# A31C11x register map
Vendor: ABOV Semiconductor Co., Ltd.; File version: 1.0
CPU: CM0PLUS r0p1, little endian, no MPU, no FPU, VTOR, 2 interrupt priority bits
Registers are 32-bit, read-write, reset 0x0 unless marked. A register's access mark holds for its fields unless they carry their own. Offsets are from the block's base; [hi:lo] are bit positions; lines under a group give offsets from that group; {n}, {i} and the like mark numbered series; 'fields as' and 'values as' point back to an identical list.

## SCU — System Control Unit
Base 0x40000000
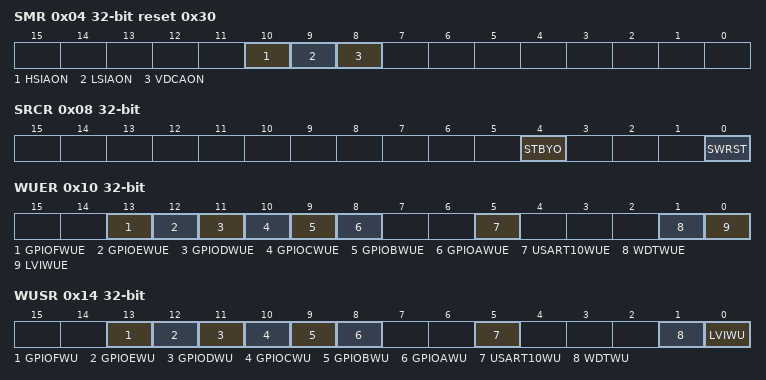
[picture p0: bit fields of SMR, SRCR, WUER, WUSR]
0x04 SMR reset 0x30 — System Mode Register
  [10] HSIAON — HSI enablement in DEEP-SLEEP mode
  [9] LSIAON — LSI enablement in DEEP-SLEEP mode
  [8] VDCAON — VDC enablement in DEEP-SLEEP mode
0x08 SRCR — System reset control Register
  [4] STBYO — Inversion selection for the STBYO pin's output
  [0] SWRST wo — Internal soft reset activation bit (Check SWRST in SCU_RSER for reset)
0x10 WUER — Wake-up Source Enable Register
  [13] GPIOFWUE — Whether or not to use the GPIOF port event as a wake-up source
  [12] GPIOEWUE — Whether or not to use the GPIOE port event as a wake-up source
  [11] GPIODWUE — Whether or not to use the GPIOD port event as a wake-up source
  [10] GPIOCWUE — Whether or not to use the GPIOC port event as a wake-up source
  [9] GPIOBWUE — Whether or not to use the GPIOB port event as a wake-up source
  [8] GPIOAWUE — Whether or not to use the GPIOA port event as a wake-up source
  [5] USART10WUE — Whether or not to use the USART10 event as a wake-up source
  [1] WDTWUE — Whether or not to use the WDT event as a wake-up source
  [0] LVIWUE — Whether or not to use the LVI event as a wake-up source
0x14 WUSR ro — Wake-up Source Status Register
  [13] GPIOFWU — GPIOF port event Wake-up status
  [12] GPIOEWU — GPIOE port event Wake-up status
  [11] GPIODWU — GPIOD port event Wake-up status
  [10] GPIOCWU — GPIOC port event Wake-up status
  [9] GPIOBWU — GPIOB port event Wake-up status
  [8] GPIOAWU — GPIOA port event Wake-up status
  [5] USART10WU — USART10 event Wake-up status
  [1] WDTWU — WDT event Wake-up status
  [0] LVIWU — LVI event Wake-up status
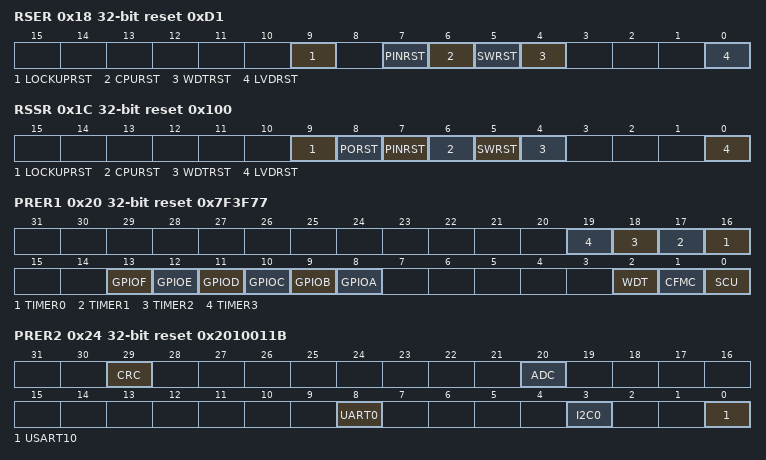
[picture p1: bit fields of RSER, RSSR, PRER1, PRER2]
0x18 RSER reset 0xD1 — Reset Source Enable Register
  [9] LOCKUPRST — Whether to enable or disable the CPU lock-up reset signal
  [7] PINRST — Whether to enable or disable the external-pin reset signal
  [6] CPURST — Whether to enable or disable the CPU request reset signal
  [5] SWRST — Whether to enable or disable the software reset signal
  [4] WDTRST — Whether to enable or disable the WDT reset signal
  [0] LVDRST — Whether to enable or disable the LVD reset signal
0x1C RSSR reset 0x100 — Reset Source Status Register
  [9] LOCKUPRST — Whether or not the CPU lock-up reset has occurred
  [8] PORST — Whether or not the POR reset has occurred
  [7] PINRST — Whether or not the external pin reset has occurred
  [6] CPURST — Whether or not the CPU core reset has occurred
  [5] SWRST — Whether or not the software reset has occurred
  [4] WDTRST — Whether or not the WDT reset has occurred
  [0] LVDRST — Whether or not the LVD reset has occurred
0x20 PRER1 reset 0x7F3F77 — Peripheral Reset Enable Register1
  [n+16] TIMER{n} (n=0..3) — TIMER{n} Reset Mask
  [13] GPIOF — GPIOF Reset Mask
  [12] GPIOE — GPIOE Reset Mask
  [11] GPIOD — GPIOD Reset Mask
  [10] GPIOC — GPIOC Reset Mask
  [9] GPIOB — GPIOB Reset Mask
  [8] GPIOA — GPIOA Reset Mask
  [2] WDT — WDT Reset Mask
  [1] CFMC — CFMC Reset Mask
  [0] SCU — SCU Reset Mask
0x24 PRER2 reset 0x2010011B — Peripheral Reset Setting Register2
  [29] CRC — CRC Reset Mask
  [20] ADC — ADC Reset Mask
  [8] UART0 — UART0 Reset Mask
  [3] I2C0 — I2C0 Reset Mask
  [0] USART10 — USART10 Reset Mask
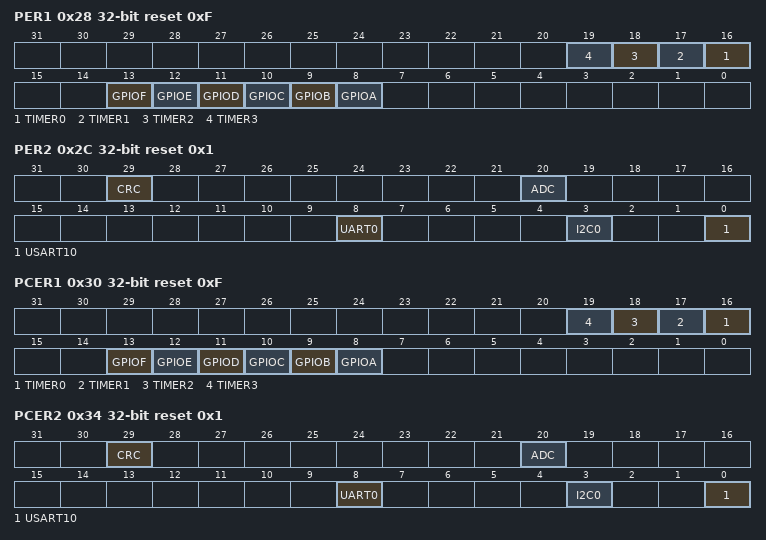
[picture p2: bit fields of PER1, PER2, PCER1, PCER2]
0x28 PER1 reset 0xF — Peripheral Enable Register1
  [n+16] TIMER{n} (n=0..3) — Whether to enable or disable TIMER{n}
  [13] GPIOF — Whether to enable or disable GPIOF
  [12] GPIOE — Whether to enable or disable GPIOE
  [11] GPIOD — Whether to enable or disable GPIOD
  [10] GPIOC — Whether to enable or disable GPIOC
  [9] GPIOB — Whether to enable or disable GPIOB
  [8] GPIOA — Whether to enable or disable GPIOA
0x2C PER2 reset 0x1 — Peripheral Enable Register2
  [29] CRC — Whether to enable or disable CRC
  [20] ADC — Whether to enable or disable ADC
  [8] UART0 — Whether to enable or disable UART0
  [3] I2C0 — Whether to enable or disable I2C0
  [0] USART10 — Whether to enable or disable USART10
0x30 PCER1 reset 0xF — Peripheral Clock Enable Register1
  [n+16] TIMER{n} (n=0..3) — Whether to enable or disable the clock to TIMER{n}
  [13] GPIOF — Whether to enable or disable the clock to GPIOF
  [12] GPIOE — Whether to enable or disable the clock to GPIOE
  [11] GPIOD — Whether to enable or disable the clock to GPIOD
  [10] GPIOC — Whether to enable or disable the clock to GPIOC
  [9] GPIOB — Whether to enable or disable the clock to GPIOB
  [8] GPIOA — Whether to enable or disable the clock to GPIOA
0x34 PCER2 reset 0x1 — Peripheral Clock Enable Register2
  [29] CRC — Whether to enable or disable the clock to CRC
  [20] ADC — Whether to enable or disable the clock to ADC
  [8] UART0 — Whether to enable or disable the clock to UART0
  [3] I2C0 — Whether to enable or disable the clock to I2C0
  [0] USART10 — Whether to enable or disable the clock to USART10
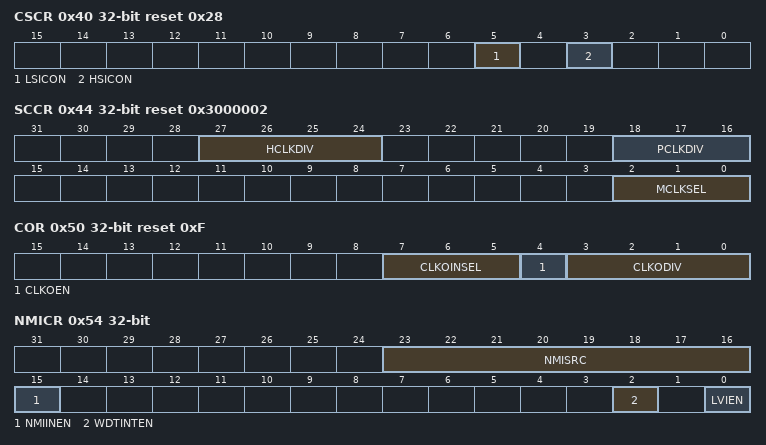
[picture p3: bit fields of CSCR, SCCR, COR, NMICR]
0x40 CSCR reset 0x28 — Clock Source Control Register
  [5] LSICON — Low speed internal oscillator control
  [3] HSICON — High speed internal oscillator control
0x44 SCCR reset 0x3000002 — System clock control register
  [27:24] HCLKDIV — Clock divider for HCLK input
    9=MCLK_DIV_BY_512 (HCLK=MCLK_div_512); 8=MCLK_DIV_BY_256 (HCLK=MCLK_div_256); 7=MCLK_DIV_BY_128 (HCLK=MCLK_div_128); 6=MCLK_DIV_BY_64 (HCLK=MCLK_div_64); 5=MCLK_DIV_BY_32 (HCLK=MCLK_div_32); 4=MCLK_DIV_BY_16 (HCLK=MCLK_div_16); 3=MCLK_DIV_BY_8 (HCLK=MCLK_div_8); 2=MCLK_DIV_BY_4 (HCLK=MCLK_div_4); 1=MCLK_DIV_BY_2 (HCLK=MCLK_div_2); 0=MCLK_DIV_BY_1 (HCLK=MCLK_div_1)
  [18:16] PCLKDIV — Clock divider for PCLK input
    4=HCLK_DIV_BY_16 (PCLK=HCLK_div_16); 3=HCLK_DIV_BY_8 (PCLK=HCLK_div_8); 2=HCLK_DIV_BY_4 (PCLK=HCLK_div_4); 1=HCLK_DIV_BY_2 (PCLK=HCLK_div_2); 0=MCLK_DIV_BY_1 (HCLK=MCLK_div_1)
  [2:0] MCLKSEL — Main system clock selection
    2=HSI (system clock is HSI); 0=LSI (system clock is LSI)
0x50 COR reset 0xF — Clock Output Setting Register
  [7:5] CLKOINSEL — Selection of the clock to send a signal from CLKO
    5=HSI (Output clock is HSI); 4=MCLK (Output clock is MCLK); 0=LSI (Output clock is LSI)
  [4] CLKOEN — Clock output use
  [3:0] CLKODIV — Clock output divider value.
0x54 NMICR — NMI Control Register
  [23:16] NMISRC — NMI source selection bit
  [15] NMIINEN — Whether to enable or disable the NMIs (Interrupts that have been specified as NMI sources)
  [2] WDTINTEN — Whether to enable or disable the WDT interrupt as an NMI
  [0] LVIEN — Whether to enable or disable the LVI error interrupt as an NMI
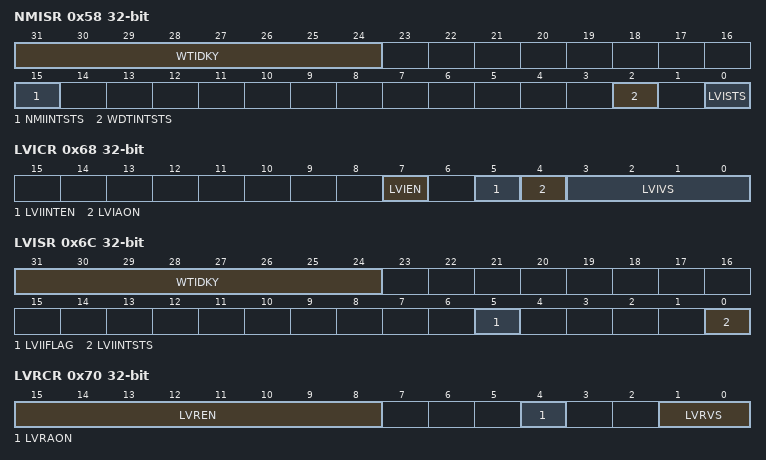
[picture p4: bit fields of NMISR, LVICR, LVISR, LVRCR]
0x58 NMISR — NMI Status Register
  [31:24] WTIDKY wo — Write identification key
  [15] NMIINTSTS ro — Whether or not an NMI has occurred (The flag can be cleared by writing to the triggered NMIs bit.)
  [2] WDTINTSTS — Whether or not the WDT interrupt has occurred
  [0] LVISTS — Whether or not the LVI interrupt has occurred
0x64 VDCCON reset 0x7F — VDC Control Register
  [7:0] VDCWDLY — VDC Warm-up Delay Count Value
0x68 LVICR — Low Voltage Indicator Control Register
  [7] LVIEN — Whether to enable or disable the LVI
  [5] LVIINTEN — Whether to enable or disable the LVI interrupt
  [4] LVIAON — Whether or not to deactivate the LVI in DEEP-SLEEP mode
  [3:0] LVIVS — LVI interrupt voltage selection bits
    0=2_20 (2.21V); 1=3_00 (3.01V); 2=4.00V; 3=4_50 (4.51V)
0x6C LVISR — Low Voltage Indicator Status Register
  [31:24] WTIDKY wo — Write identification key
  [5] LVIIFLAG — LVI interrupt flag
  [0] LVIINTSTS ro — Whether or not the LVI interrupt is active (Raw data)
0x70 LVRCR — Low Voltage Reset Control Register
  [15:8] LVREN — LVR reset operation control master configuration
    0=ENABLE (Enable LVR); 170=DISABLE (Disable LVR)
  [4] LVRAON — Whether or not to deactivate the LVR reset in DEEP-SLEEP mode
  [1:0] LVRVS — LVR voltage selection bits
    0=1.60V; 1=2.70V; 2=3.70V; 3=4_20 (4.22V)
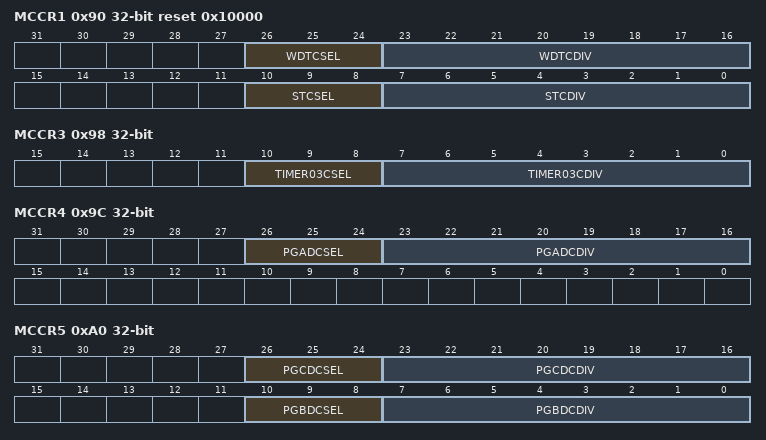
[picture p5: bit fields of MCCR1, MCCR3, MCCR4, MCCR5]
0x90 MCCR1 reset 0x10000 — MISC Clock Control Register1
  [26:24] WDTCSEL — WDT Clock Source Selection Bit
    5=HSI (Clock Source is HSI); 0=LSI (Clock Source is LSI)
  [23:16] WDTCDIV — WDT Clock N divider
  [10:8] STCSEL — SYSTIC Clock Source Selection Bit
    5=HSI (Clock Source is HSI); 4=MCLK (Clock Source is MCLK); 0=LSI (Clock Source is LSI)
  [7:0] STCDIV — SYSTIC Clock N divider
0x98 MCCR3 — MISC Clock Control Register3
  [10:8] TIMER03CSEL — TIMER0-3 Clock Source Selection Bit
    values as MCCR1.STCSEL
  [7:0] TIMER03CDIV — TIMER0-3 Clock N divider
0x9C MCCR4 — MISC Clock Control Register4
  [26:24] PGADCSEL — Clock source for port group A debouncing (PA, PB)
    values as MCCR1.STCSEL
  [23:16] PGADCDIV — Clock divider N for port group A debouncing (PA, PB)
0xA0 MCCR5 — MISC Clock Control Register5
  [26:24] PGCDCSEL — Clock source for port group C debouncing (PE, PF)
    values as MCCR1.STCSEL
  [23:16] PGCDCDIV — Clock divider (N) for port group C debouncing (PE, PF)
  [10:8] PGBDCSEL — Clock source for port group B debouncing (PC, PD)
    values as MCCR1.STCSEL
  [7:0] PGBDCDIV — Clock divider (N) for port group B debouncing (PC, PD)
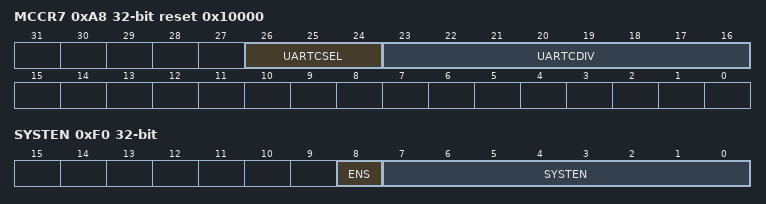
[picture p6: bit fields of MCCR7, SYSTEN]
0xA8 MCCR7 reset 0x10000 — MISC Clock Control Register7
  [26:24] UARTCSEL — UART Clock Source Selection Bit
    values as MCCR1.STCSEL
  [23:16] UARTCDIV — UART Clock N divider
0xF0 SYSTEN — System Access Key Register
  [8] ENS ro — Enable SCU registers enable status bit
  [7:0] SYSTEN wo — SCU register access enable key
0xF4 BOOTSR reset 0x1 — System Boot Status Register
  [0] BC wo — Boot configuration status
